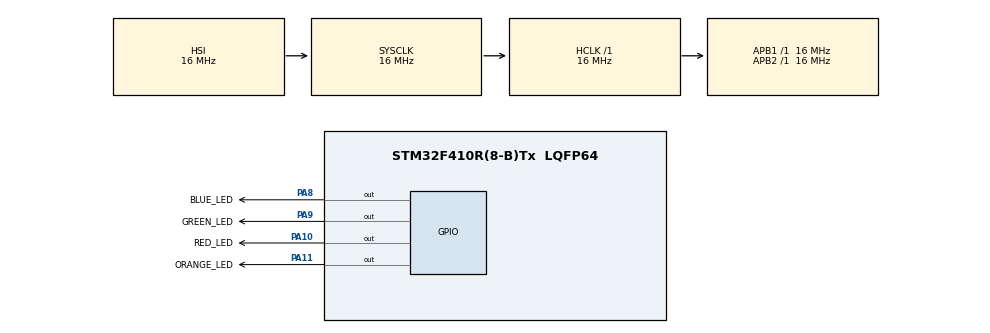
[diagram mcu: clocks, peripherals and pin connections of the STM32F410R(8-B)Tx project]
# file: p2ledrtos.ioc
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FREERTOS.Tasks01=defaultTask,24,128,StartDefaultTask,Default,NULL,Dynamic,NULL,NULL;FlashGreenLedTa,24,128,StartFlashGreenTask,Default,NULL,Dynamic,NULL,NULL;FlashRedLedTask,24,128,StartFlashRedTask,Default,NULL,Dynamic,NULL,NULL
FREERTOS.configTOTAL_HEAP_SIZE=3600
Mcu.Family=STM32F4
Mcu.Name=STM32F410R(8-B)Tx
Mcu.Package=LQFP64
NVIC.PriorityGroup=NVIC_PRIORITYGROUP_4
NVIC.TIM1_UP_IRQn=true\:15\:0\:false\:false\:true\:false\:false\:true\:true
NVIC.TimeBase=TIM1_UP_IRQn
NVIC.TimeBaseIP=TIM1
PA10.GPIO_Label=RED_LED
PA10.Signal=GPIO_Output
PA11.GPIO_Label=ORANGE_LED
PA11.Signal=GPIO_Output
PA8.GPIO_Label=BLUE_LED
PA8.Signal=GPIO_Output
PA9.GPIO_Label=GREEN_LED
PA9.Signal=GPIO_Output
PH0\ -\ OSC_IN.Mode=HSE-External-Oscillator
PH0\ -\ OSC_IN.Signal=RCC_OSC_IN
PH1\ -\ OSC_OUT.Mode=HSE-External-Oscillator
PH1\ -\ OSC_OUT.Signal=RCC_OSC_OUT
ProjectManager.HeapSize=0x200
ProjectManager.StackSize=0x400
ProjectManager.TargetToolchain=STM32CubeIDE
RCC.AHBFreq_Value=16000000
RCC.APB1Freq_Value=16000000
RCC.APB2Freq_Value=16000000
RCC.CortexFreq_Value=16000000
RCC.HSE_VALUE=25000000
RCC.HSI_VALUE=16000000
RCC.LSE_VALUE=32768
RCC.SYSCLKFreq_VALUE=16000000
RCC.VCOOutputFreq_Value=192000000
VP_FREERTOS_VS_CMSIS_V2.Mode=CMSIS_V2
VP_SYS_VS_tim1.Mode=TIM1
board=custom

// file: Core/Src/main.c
/* USER CODE BEGIN Header */
/**
  ******************************************************************************
  * @file           : main.c
  * @brief          : Main program body
  ******************************************************************************
  * @attention
  *
  * Copyright (c) 2024 STMicroelectronics.
  * All rights reserved.
  *
  * This software is licensed under terms that can be found in the LICENSE file
  * in the root directory of this software component.
  * If no LICENSE file comes with this software, it is provided AS-IS.
  *
  ******************************************************************************
  */
/* USER CODE END Header */
#include "main.h"
#include "cmsis_os.h"

/* Definitions for defaultTask */
osThreadId_t defaultTaskHandle;
const osThreadAttr_t defaultTask_attributes = {
  .name = "defaultTask",
  .stack_size = 128 * 4,
  .priority = (osPriority_t) osPriorityNormal,
};
/* Definitions for FlashGreenLedTa */
osThreadId_t FlashGreenLedTaHandle;
const osThreadAttr_t FlashGreenLedTa_attributes = {
  .name = "FlashGreenLedTa",
  .stack_size = 128 * 4,
  .priority = (osPriority_t) osPriorityNormal,
};
/* Definitions for FlashRedLedTask */
osThreadId_t FlashRedLedTaskHandle;
const osThreadAttr_t FlashRedLedTask_attributes = {
  .name = "FlashRedLedTask",
  .stack_size = 128 * 4,
  .priority = (osPriority_t) osPriorityNormal,
};

void SystemClock_Config(void);
static void MX_GPIO_Init(void);
void StartDefaultTask(void *argument);
void StartFlashGreenTask(void *argument);
void StartFlashRedTask(void *argument);

int main(void)
{

  /* MCU Configuration--------------------------------------------------------*/

  /* Reset of all peripherals, Initializes the Flash interface and the Systick. */
  HAL_Init();

  /* Configure the system clock */
  SystemClock_Config();

  /* Initialize all configured peripherals */
  MX_GPIO_Init();

  /* Init scheduler */
  osKernelInitialize();

  /* Create the thread(s) */
  /* creation of defaultTask */
  defaultTaskHandle = osThreadNew(StartDefaultTask, NULL, &defaultTask_attributes);

  /* creation of FlashGreenLedTa */
  FlashGreenLedTaHandle = osThreadNew(StartFlashGreenTask, NULL, &FlashGreenLedTa_attributes);

  /* creation of FlashRedLedTask */
  FlashRedLedTaskHandle = osThreadNew(StartFlashRedTask, NULL, &FlashRedLedTask_attributes);

  /* Start scheduler */
  osKernelStart();

  /* We should never get here as control is now taken by the scheduler */

  /* Infinite loop */
  while (1)
  {

  }
}

void SystemClock_Config(void)
{
  RCC_OscInitTypeDef RCC_OscInitStruct = {0};
  RCC_ClkInitTypeDef RCC_ClkInitStruct = {0};

  /** Configure the main internal regulator output voltage
  */
  __HAL_RCC_PWR_CLK_ENABLE();
  __HAL_PWR_VOLTAGESCALING_CONFIG(PWR_REGULATOR_VOLTAGE_SCALE1);

  /** Initializes the RCC Oscillators according to the specified parameters
  * in the RCC_OscInitTypeDef structure.
  */
  RCC_OscInitStruct.OscillatorType = RCC_OSCILLATORTYPE_HSI;
  RCC_OscInitStruct.HSIState = RCC_HSI_ON;
  RCC_OscInitStruct.HSICalibrationValue = RCC_HSICALIBRATION_DEFAULT;
  RCC_OscInitStruct.PLL.PLLState = RCC_PLL_NONE;
  if (HAL_RCC_OscConfig(&RCC_OscInitStruct) != HAL_OK)
  {
    Error_Handler();
  }

  /** Initializes the CPU, AHB and APB buses clocks
  */
  RCC_ClkInitStruct.ClockType = RCC_CLOCKTYPE_HCLK|RCC_CLOCKTYPE_SYSCLK
                              |RCC_CLOCKTYPE_PCLK1|RCC_CLOCKTYPE_PCLK2;
  RCC_ClkInitStruct.SYSCLKSource = RCC_SYSCLKSOURCE_HSI;
  RCC_ClkInitStruct.AHBCLKDivider = RCC_SYSCLK_DIV1;
  RCC_ClkInitStruct.APB1CLKDivider = RCC_HCLK_DIV1;
  RCC_ClkInitStruct.APB2CLKDivider = RCC_HCLK_DIV1;

  if (HAL_RCC_ClockConfig(&RCC_ClkInitStruct, FLASH_LATENCY_0) != HAL_OK)
  {
    Error_Handler();
  }
}

static void MX_GPIO_Init(void)
{
  GPIO_InitTypeDef GPIO_InitStruct = {0};

  /* GPIO Ports Clock Enable */
  __HAL_RCC_GPIOH_CLK_ENABLE();
  __HAL_RCC_GPIOA_CLK_ENABLE();

  /*Configure GPIO pin Output Level */
  HAL_GPIO_WritePin(GPIOA, BLUE_LED_Pin|GREEN_LED_Pin|RED_LED_Pin|ORANGE_LED_Pin, GPIO_PIN_RESET);

  /*Configure GPIO pins : BLUE_LED_Pin GREEN_LED_Pin RED_LED_Pin ORANGE_LED_Pin */
  GPIO_InitStruct.Pin = BLUE_LED_Pin|GREEN_LED_Pin|RED_LED_Pin|ORANGE_LED_Pin;
  GPIO_InitStruct.Mode = GPIO_MODE_OUTPUT_PP;
  GPIO_InitStruct.Pull = GPIO_NOPULL;
  GPIO_InitStruct.Speed = GPIO_SPEED_FREQ_LOW;
  HAL_GPIO_Init(GPIOA, &GPIO_InitStruct);

}

void StartDefaultTask(void *argument)
{
  for(;;)
  {
    osDelay(1);
  }
}

void StartFlashGreenTask(void *argument)
{
  /* USER CODE BEGIN StartFlashGreenTask */
  /* Infinite loop */
  for(;;)
  {
	  // 1. Turn the Blue LED on (Task is active)
	  HAL_GPIO_WritePin(GPIOA, BLUE_LED_Pin, GPIO_PIN_SET);

	  // 2. Flash the Green LED at 20 Hz for 4 seconds (Task execution)
	  for (int i = 0; i < 80; ++i) {
		  HAL_GPIO_TogglePin(GPIOA, GREEN_LED_Pin);
		  osDelay(50);  // 50ms delay = 20 Hz toggling
	  }

	  // 3. Turn off both LEDs (Task complete)
	  HAL_GPIO_WritePin(GPIOA, GREEN_LED_Pin, GPIO_PIN_RESET);
	  HAL_GPIO_WritePin(GPIOA, BLUE_LED_Pin, GPIO_PIN_RESET);

	  // 4. Suspend task for 6 seconds (10 - 4 = 6 seconds)
	  osDelay(6000);
  }
  /* USER CODE END StartFlashGreenTask */
}

void StartFlashRedTask(void *argument)
{
  /* USER CODE BEGIN StartFlashRedTask */
  /* Infinite loop */
  for(;;)
  {
	  // 1. Turn the Orange LED on (Task is active)
	  HAL_GPIO_WritePin(GPIOA, ORANGE_LED_Pin, GPIO_PIN_SET);

	   // 2. Flash the Red LED at 20 Hz for 0.5 seconds (Task execution)
	   for (int i = 0; i < 10; ++i) {
		   HAL_GPIO_TogglePin(GPIOA, RED_LED_Pin);
		   osDelay(50);  // 50ms delay = 20 Hz toggling
	   }

	   // 3. Turn off both LEDs (Task complete)
	   HAL_GPIO_WritePin(GPIOA, RED_LED_Pin, GPIO_PIN_RESET);
	   HAL_GPIO_WritePin(GPIOA, ORANGE_LED_Pin, GPIO_PIN_RESET);

	   // 4. Suspend task for 1.5 seconds (2 - 0.5 = 1.5 seconds)
	   osDelay(1500);;
  }
  /* USER CODE END StartFlashRedTask */
}

void HAL_TIM_PeriodElapsedCallback(TIM_HandleTypeDef *htim)
{
  if (htim->Instance == TIM1) {
    HAL_IncTick();
  }
}

void Error_Handler(void)
{
  __disable_irq();
  while (1)
  {
  }
}
